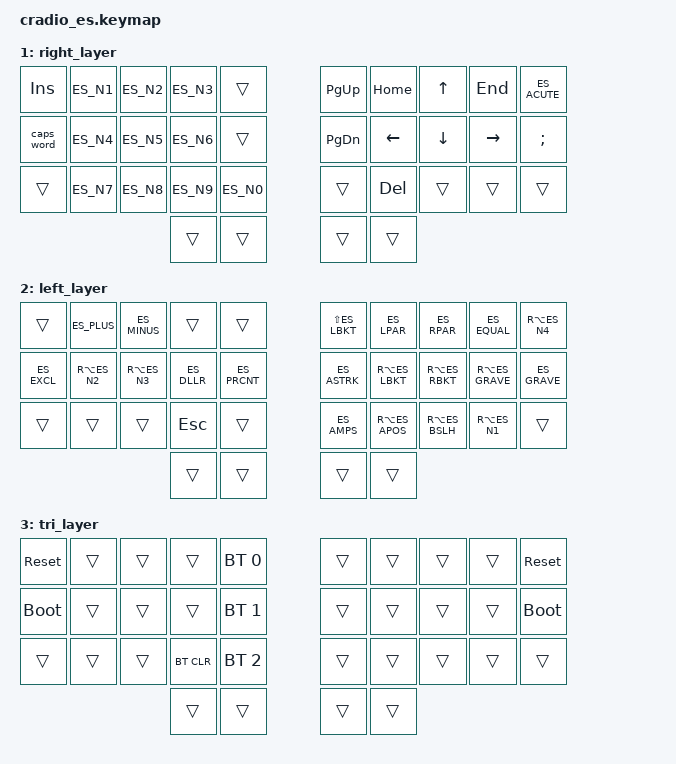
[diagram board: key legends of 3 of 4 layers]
// Copyright (c) 2022 The ZMK Contributors
// SPDX-License-Identifier: MIT

#include <behaviors.dtsi>
#include <dt-bindings/zmk/keys.h>
#include <dt-bindings/zmk/bt.h>
#include "keys_es.h"

// Home row mods macro
#define HRML(k1,k2,k3,k4) &ht LSHFT k1  &ht LALT k2  &ht LCTRL k3  &ht LGUI k4
#define HRMR(k1,k2,k3,k4) &ht RGUI k1  &ht RCTRL k2  &ht RALT k3  &ht RSHFT k4

/ {
    behaviors {
        ht: hold_tap {
            compatible = "zmk,behavior-hold-tap";
            #binding-cells = <2>;
            flavor = "tap-preferred";
            tapping-term-ms = <220>;
            quick-tap-ms = <150>;
            require-prior-idle-ms = <100>;
            bindings = <&kp>, <&kp>;
        };
    };

    conditional_layers {
        compatible = "zmk,conditional-layers";
        tri_layer {
            if-layers = <1 2>;
            then-layer = <3>;
        };
    };

    keymap {
        compatible = "zmk,keymap";
        default_layer {
            bindings = <
        //╭──────────┬──────────┬──────────┬──────────┬──────────╮   ╭──────────┬──────────┬──────────┬──────────┬──────────╮
        //│  Q       │  W       │  E       │  R       │  T       │   │  Y       │  U       │  I       │  O       │ P        │
            &kp ES_Q   &kp ES_W   &kp ES_E   &kp ES_R   &kp ES_T       &kp ES_Y   &kp ES_U   &kp ES_I   &kp ES_O   &kp ES_P
        //├──────────┼──────────┼──────────┼──────────┼──────────┤   ├──────────┼──────────┼──────────┼──────────┼──────────┤
        //│  A       │  S       │  D       │  F       │  G       │   │  H       │  J       │  K       │  L       │ Ñ        │
            HRML(ES_A, ES_S,      ES_D,     ES_F)     &kp ES_G        &kp ES_H   HRMR(ES_J,  ES_K,     ES_L,      ES_N)
        //├──────────┼──────────┼──────────┼──────────┼──────────┤   ├──────────┼──────────┼──────────┼──────────┼──────────┤
        //│  Z       │  X       │  C       │  V       │  B       │   │  N       │  M       │ , ;      │ . :      │ tilde    │
            &kp ES_Z   &kp ES_X   &kp ES_C   &kp ES_V   &kp ES_B    &kp ES_N   &kp ES_M   &kp ES_COMMA &kp ES_DOT &kp ES_ACUTE
        //╰──────────┴──────────┴──────────┼──────────┼──────────┤   ├──────────┼──────────┼──────────┴──────────┴──────────╯
                                            &lt 2 TAB   &kp ENTER   &kp ES_SPACE  &lt 1 BSPC
        //                                 ╰──────────┴──────────╯   ╰──────────┴──────────╯
            >;
        };

        right_layer {
            bindings = <
        //╭──────────┬──────────┬──────────┬──────────┬──────────╮   ╭──────────┬──────────┬──────────┬──────────┬──────────╮
        //│ INSERT   │  1  !  | │  2  "  # │  3  ·  # │          │   │ PAGE UP  │ INICIO   │ UP   /\  │ END      │  tilde   │
            &kp INS    &kp ES_N1  &kp ES_N2  &kp ES_N3  &trans         &kp PG_UP  &kp HOME   &kp UP     &kp END   &kp ES_ACUTE
        //├──────────┼──────────┼──────────┼──────────┼──────────┤   ├──────────┼──────────┼──────────┼──────────┼──────────┤
        //│ CAPS     │  4  $  ~ │  5  %  ~ │  6  &  ¬ │          │   │ PAGE DN  │ LEFT <   │ DOWN \/  │ RIGHT >  │  ;       │
           &caps_word  &kp ES_N4  &kp ES_N5  &kp ES_N6  &trans         &kp PG_DN  &kp LEFT   &kp DOWN   &kp RIGHT   &kp SEMI
        //├──────────┼──────────┼──────────┼──────────┼──────────┤   ├──────────┼──────────┼──────────┼──────────┼──────────┤
        //│          │  7  /    │  8       │  9       │  0  =    │   │          │ DELETE   │          │          │          │
           &trans     &kp ES_N7  &kp ES_N8  &kp ES_N9  &kp ES_N0      &trans     &kp DEL    &trans     &trans     &trans
        //╰──────────┴──────────┴──────────┼──────────┼──────────┤   ├──────────┼──────────┼──────────┴──────────┴──────────╯
                                             &trans     &trans         &trans     &trans
        //                                 ╰──────────┴──────────╯   ╰──────────┴──────────╯
            >;
        };

        left_layer {
            bindings = 
        //╭──────────┬──────────┬──────────┬──────────┬──────────╮   ╭──────────┬──────────┬──────────┬──────────┬──────────╮
        //│          │    +     │  -       │          │          │   │  ^       │  (       │  )       │    =     │  ~       │
            &trans &kp ES_PLUS &kp ES_MINUS &trans  &trans   &kp LS(ES_LBKT) &kp ES_LPAR &kp ES_RPAR &kp ES_EQUAL &kp RA(ES_N4)
        //├──────────┼──────────┼──────────┼──────────┼──────────┤   ├──────────┼──────────┼──────────┼──────────┼──────────┤
        //│  !       │  @       │  #       │  $       │  %       │   │  *       │  [       │  ]       │  \       │  `       │
        &kp ES_EXCL &kp RA(ES_N2) &kp RA(ES_N3) &kp ES_DLLR &kp ES_PRCNT &kp ES_ASTRK &kp RA(ES_LBKT) &kp RA(ES_RBKT) &kp RA(ES_GRAVE) &kp ES_GRAVE
        //├──────────┼──────────┼──────────┼──────────┼──────────┤   ├──────────┼──────────┼──────────┼──────────┼──────────┤
        //│          │          │          │ ESCAPE   │          │   │  &       │  {       │  }       │  │       │          │
            &trans     &trans     &trans     &kp ESC    &trans   &kp ES_AMPS &kp RA(ES_APOS) &kp RA(ES_BSLH) &kp RA(ES_N1) &trans
        //╰──────────┴──────────┴──────────┼──────────┼──────────┤   ├──────────┼──────────┼──────────┴──────────┴──────────╯
                                             &trans     &trans         &trans     &trans
        //                                 ╰──────────┴──────────╯   ╰──────────┴──────────╯
            >;
        };

        tri_layer {
            bindings = <
        //╭──────────┬──────────┬──────────┬──────────┬──────────╮   ╭──────────┬──────────┬──────────┬──────────┬──────────╮
        //│ RESET    │          │          │          │PROFILE 0 │   │          │          │          │          │  RESET   │
           &sys_reset  &trans     &trans     &trans    &bt BT_SEL 0    &trans     &trans     &trans     &trans    &sys_reset
        //├──────────┼──────────┼──────────┼──────────┼──────────┤   ├──────────┼──────────┼──────────┼──────────┼──────────┤
        //│BOOTLOADER│          │          │          │PROFILE 1 │   │          │          │          │          │BOOTLOADER│
          &bootloader  &trans     &trans     &trans    &bt BT_SEL 1    &trans     &trans     &trans     &trans    &bootloader
        //├──────────┼──────────┼──────────┼──────────┼──────────┤   ├──────────┼──────────┼──────────┼──────────┼──────────┤
        //│          │          │          │ CLEAR BT │PROFILE 2 │   │          │          │          │          │          │
            &trans     &trans     &trans    &bt BT_CLR &bt BT_SEL 2    &trans     &trans     &trans     &trans     &trans
        //╰──────────┴──────────┴──────────┼──────────┼──────────┤   ├──────────┼──────────┼──────────┴──────────┴──────────╯
                                             &trans     &trans         &trans     &trans
        //                                 ╰──────────┴──────────╯   ╰──────────┴──────────╯
            >;
        };
    };
};
